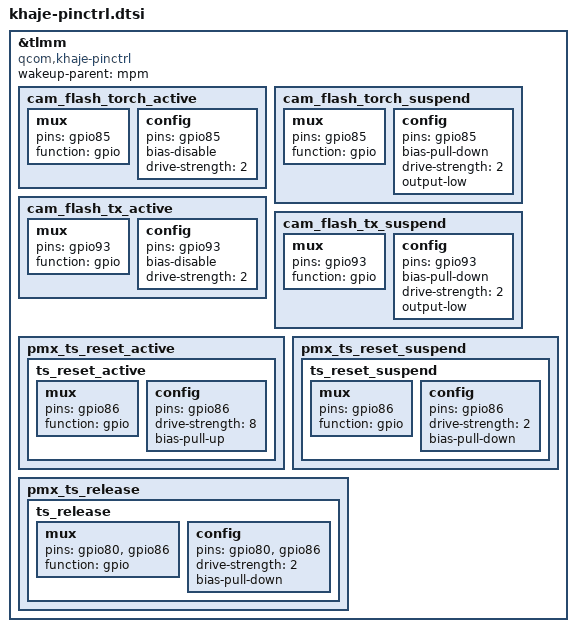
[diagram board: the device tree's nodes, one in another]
#include "bengal-pinctrl.dtsi"

&tlmm {
		compatible = "qcom,khaje-pinctrl";
		wakeup-parent = <&mpm>;

		cam_flash_torch_active: cam_flash_torch_active {
			/* TORCH */
			mux {
				pins = "gpio85";
				function = "gpio";
			};

			config {
				pins = "gpio85";
				bias-disable; /* No PULL */
				drive-strength = <2>; /* 2 MA */
			};
		};

		cam_flash_torch_suspend: cam_flash_torch_suspend {
			/* TORCH */
			mux {
				pins = "gpio85";
				function = "gpio";
			};

			config {
				pins = "gpio85";
				bias-pull-down; /* PULL DOWN */
				drive-strength = <2>; /* 2 MA */
				output-low;
			};
		};

		cam_flash_tx_active: cam_flash_tx_active {
			/* TX */
			mux {
				pins = "gpio93";
				function = "gpio";
			};

			config {
				pins = "gpio93";
				bias-disable; /* No PULL */
				drive-strength = <2>; /* 2 MA */
			};
		};

		cam_flash_tx_suspend: cam_flash_tx_suspend {
			/* TX */
			mux {
				pins = "gpio93";
				function = "gpio";
			};

			config {
				pins = "gpio93";
				bias-pull-down; /* PULL DOWN */
				drive-strength = <2>; /* 2 MA */
				output-low;
			};
		};

		pmx_ts_reset_active {
			ts_reset_active: ts_reset_active {
				mux {
					pins = "gpio86";
					function = "gpio";
				};

				config {
					pins = "gpio86";
					drive-strength = <8>;
					bias-pull-up;
				};
			};
		};

		pmx_ts_reset_suspend {
			ts_reset_suspend: ts_reset_suspend {
				mux {
					pins = "gpio86";
					function = "gpio";
				};

				config {
					pins = "gpio86";
					drive-strength = <2>;
					bias-pull-down;
				};
			};
		};

		pmx_ts_release {
			ts_release: ts_release {
				mux {
					pins = "gpio80", "gpio86";
					function = "gpio";
				};

				config {
					pins = "gpio80", "gpio86";
					drive-strength = <2>;
					bias-pull-down;
				};
			};
		};
};
